# PIC32MX170F512H device description
Architecture: MIPS; Family: PIC32MX; Series: PIC32MX
Registers are 32-bit, read-write, no defined reset value unless marked. A register's access mark holds for its fields unless they carry their own. Offsets are from the block's base; [hi:lo] are bit positions; {n}, {i} and the like mark numbered series.

## CTMU
Instances: CTMU 0x1f80a200 in periph0
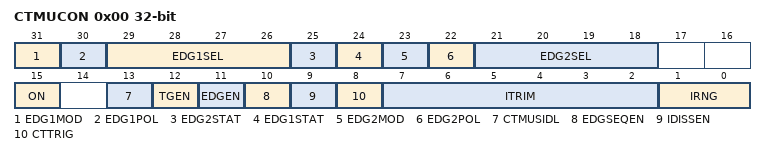
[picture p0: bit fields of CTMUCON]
0x00 CTMUCON — CTMU Control Register
  [31] EDG1MOD — Edge1 Edge Sampling Select bit
    1=Input is edge-sensitive; 0=Input is level-sensitive
  [30] EDG1POL — Edge 1 Polarity Select bit
    1=Edge1 programmed for a positive edge response; 0=Edge1 programmed for a negative edge response
  [29:26] EDG1SEL — Edge 1 Source Select bits
    15=IC4 Capture Event is selected; 14=C2OUT pin is selected; 13=C1OUT pin is selected; 12=IC3 Capture Event is selected; 11=IC2 Capture Event is selected; 10=IC1 Capture Event is selected; {v}=CTED{v-1} pin is selected (v=4..9); 3=CTED1 pin is selected; 2=CTED2 pin is selected; 1=OC1 Compare Event is selected; 0=Timer1 Event is selected
  [25] EDG2STAT — Edge2 Status bit
    1=Edge2 has occurred; 0=Edge2 has not occurred
  [24] EDG1STAT — Edge1 Status bit
    1=Edge1 has occurred; 0=Edge1 has not occurred
  [23] EDG2MOD — Edge2 Edge Sampling Select bit
    1=Input is edge-sensitive; 0=Input is level-sensitive
  [22] EDG2POL — Edge 2 Polarity Select bit
    1=Edge2 programmed for a positive edge response; 0=Edge2 programmed for a negative edge response
  [21:18] EDG2SEL — Edge 2 Source Select bits
    60=IC4 Capture Event is selected; 56=C2OUT pin is selected; 52=C1OUT pin is selected; 48=PBCLK clock is selected; 44=IC3 Capture Event is selected; 40=IC2 Capture Event is selected; 36=IC1 Capture Event is selected; 32=CTED13 pin is selected; 28=CTED12 pin is selected; 24=CTED11 pin is selected; 20=CTED10 pin is selected; 16=CTED9 pin is selected; 12=CTED1 pin is selected; 8=CTED2 pin is selected; 4=OC1 Compare Event is selected; 0=Timer1 Event is selected
  [15] ON — ON Enable bit
    1=Module is enabled; 0=Module is disabled
  [13] CTMUSIDL — Stop-in-Idle Mode bit
    1=Discontinue module operation when device enters Idle mode; 0=Continue module operation in Idle mode
  [12] TGEN — Time Generation Enable bit
    1=Enables edge delay generation; 0=Disables edge delay generation
  [11] EDGEN — Edge Enable bit
    1=Edges are not blocked; 0=Edges are blocked
  [10] EDGSEQEN — Edge Sequence Enable bit
    1=Edge1 must occur before Edge2 can occur; 0=No edge sequence is needed
  [9] IDISSEN — Analog Current Source Control bit
    1=Analog current source output is grounded; 0=Analog current source output is not grounded
  [8] CTTRIG — Trigger Control bit
    1=Trigger output is enabled; 0=Trigger output is disabled
  [7:2] ITRIM — Current Source Trim bits
    31=Maximum positive change from nominal current; 1=Minimum positive change from nominal current; 0=Nominal current output specified by IRNG; 63=Minimum negative change from nominal current; 33=Maximum negative change from nominal current
  [1:0] IRNG — Current Range Select bits
    3=100 times base current; 2=10 times base current; 1=Base current level; 0=1000 times base current

## CVR
Instances: CVR 0x1f809800 in periph0
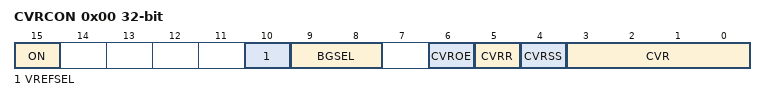
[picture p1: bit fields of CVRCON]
0x00 CVRCON — Comparator Voltage Reference Control Register
  [15] ON — Comparator Voltage Reference On bit
    1=Module is enabled. Setting this bit does not affect other bits in the register.; 0=Module is disabled and does not consume current. Clearing this bit does not affect the other bits in the register.
  [10] VREFSEL
  [9:8] BGSEL
  [6] CVROE — CVrefout Enable bit
    1=Voltage level is output on CVrefout pin; 0=Voltage level is disconnected from CVrefout pin
  [5] CVRR — CVref Range Selection bit
    1=0 to 0.67 CVrsrc with CVrsrc/24 step size; 0=0.25 CVrsrc to 0.75 CVrsrc with CVrsrc/32 step size
  [4] CVRSS — CVref Source Selection bit
    1=Comparator voltage reference source CVrsrc = (Vref+) - (Vref-); 0=Comparator voltage reference source CVrsrc = AVdd - AVss
  [3:0] CVR — CVref Value Selection
    {v}=(When CVRR is 1) CVREF is ({v}/24) * CVRSRC / (When CVRR is 0) CVREF is CVRSRC/4 + ({v}/32)*CVRSRC (v=0..15)

## Notices in the file
Copyright (c) 2019 Microchip Technology Inc.
SPDX-License-Identifier: Apache-2.0
Licensed under the Apache License, Version 2.0 (the "License");
you may not use this file except in compliance with the License.
You may obtain a copy of the License at
http://www.apache.org/licenses/LICENSE-2.0
Unless required by applicable law or agreed to in writing, software
distributed under the License is distributed on an "AS IS" BASIS,
WITHOUT WARRANTIES OR CONDITIONS OF ANY KIND, either express or implied.
See the License for the specific language governing permissions and
limitations under the License.
